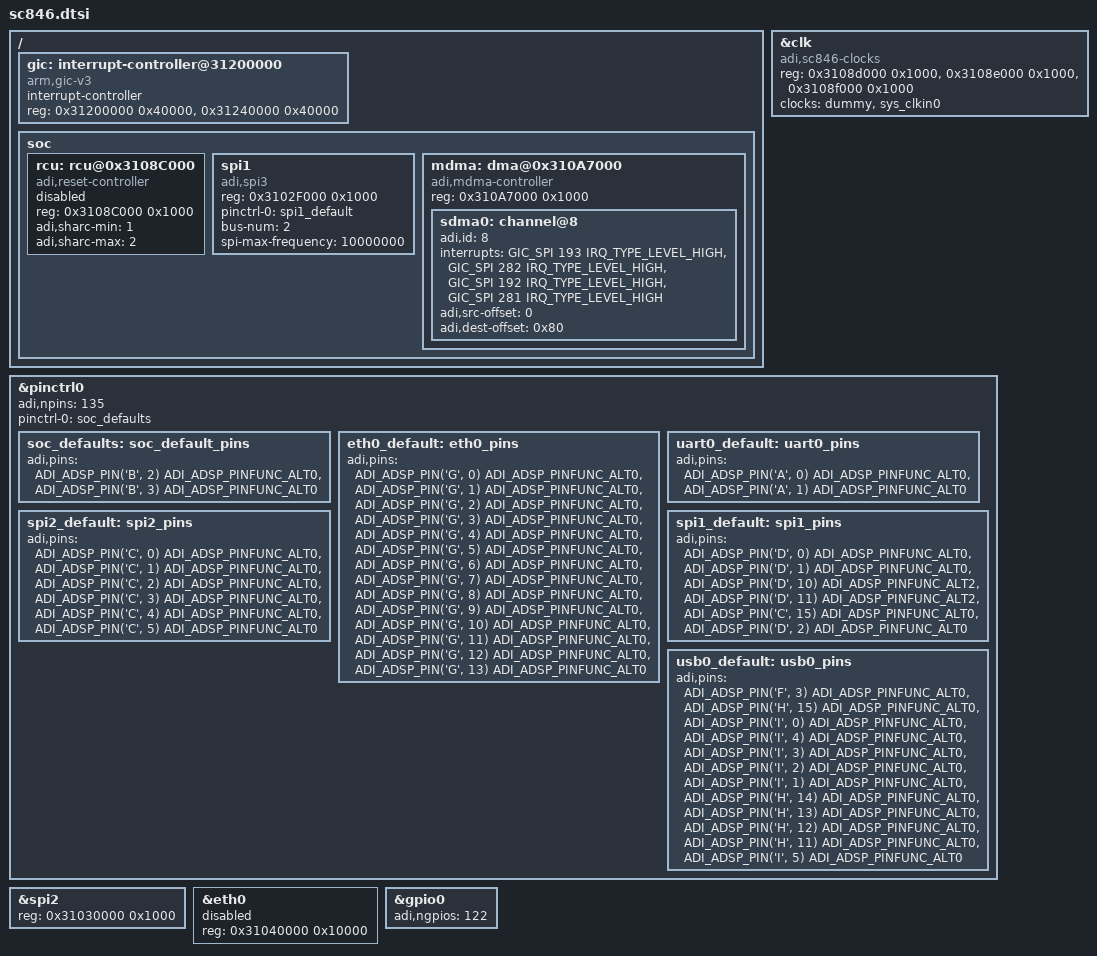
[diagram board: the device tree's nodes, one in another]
// SPDX-License-Identifier: GPL-2.0-or-later
/*
 * (C) Copyright 2026 - Analog Devices, Inc.
 */

#include "sc5xx.dtsi"

/ {
	gic: interrupt-controller@31200000 {
		compatible = "arm,gic-v3";
		#interrupt-cells = <3>;
		interrupt-controller;
		reg = <0x31200000 0x40000>,
		      <0x31240000 0x40000>;
	};

	soc {
		rcu: rcu@0x3108C000 {
			compatible = "adi,reset-controller";
			reg = <0x3108C000 0x1000>;
			adi,sharc-min = <1>;
			adi,sharc-max = <2>;
			status = "disabled";
		};

		spi1: spi1 {
			reg = <0x3102F000 0x1000>;
			compatible = "adi,spi3";
			#address-cells = <1>;
			#size-cells = <0>;
			pinctrl-names = "default";
			pinctrl-0 = <&spi1_default>;
			bus-num = <2>;
			spi-max-frequency = <10000000>;
			clock-names = "spi";
			status = "okay";
			bootph-pre-ram;
		};

		mdma: dma@0x310A7000 {
			compatible = "adi,mdma-controller";
			reg = <0x310A7000 0x1000>;
			status = "okay";
			#dma-cells = <1>;

			sdma0: channel@8 {
				adi,id = <8>;
				interrupts = <GIC_SPI 193 IRQ_TYPE_LEVEL_HIGH>,
					<GIC_SPI 282 IRQ_TYPE_LEVEL_HIGH>,
					<GIC_SPI 192 IRQ_TYPE_LEVEL_HIGH>,
					<GIC_SPI 281 IRQ_TYPE_LEVEL_HIGH>;
				interrupt-names = "complete", "error", "complete2", "error2";
				adi,src-offset = <0>;
				adi,dest-offset = <0x80>;
			};
		};
	};
};

&clk {
	reg = <0x3108d000 0x1000>,
		<0x3108e000 0x1000>,
		<0x3108f000 0x1000>;
	reg-names = "cgu0", "cgu1", "cdu";
	#clock-cells = <1>;
	clocks = <&dummy>, <&sys_clkin0>;
	clock-names = "dummy", "sys_clkin0";
	status = "okay";
	bootph-pre-ram;
};

&pinctrl0 {
	adi,npins = <135>;

	pinctrl-names = "default";

	pinctrl-0 = <&soc_defaults>;

	soc_defaults: soc_default_pins {
		bootph-pre-ram;
		adi,pins =  <ADI_ADSP_PIN('B', 2) ADI_ADSP_PINFUNC_ALT0>,
				<ADI_ADSP_PIN('B', 3) ADI_ADSP_PINFUNC_ALT0>;
	};

	eth0_default: eth0_pins {
		adi,pins = <ADI_ADSP_PIN('G', 0) ADI_ADSP_PINFUNC_ALT0>, /* management channel clock */
					<ADI_ADSP_PIN('G', 1) ADI_ADSP_PINFUNC_ALT0>,	/* management channel serial data */
					<ADI_ADSP_PIN('G', 2) ADI_ADSP_PINFUNC_ALT0>,	/* Recv Data */
					<ADI_ADSP_PIN('G', 3) ADI_ADSP_PINFUNC_ALT0>,	/* Recv Data */
					<ADI_ADSP_PIN('G', 4) ADI_ADSP_PINFUNC_ALT0>,	/* RXCLK(GigE)/Refclk(10/100) */
					<ADI_ADSP_PIN('G', 5) ADI_ADSP_PINFUNC_ALT0>,	/* RX control signal */
					<ADI_ADSP_PIN('G', 6) ADI_ADSP_PINFUNC_ALT0>,	/* Transmit Data */
					<ADI_ADSP_PIN('G', 7) ADI_ADSP_PINFUNC_ALT0>,	/* Transmit Data */
					<ADI_ADSP_PIN('G', 8) ADI_ADSP_PINFUNC_ALT0>,	/* Recv Data */
					<ADI_ADSP_PIN('G', 9) ADI_ADSP_PINFUNC_ALT0>,	/* Recv Data */
					<ADI_ADSP_PIN('G', 10) ADI_ADSP_PINFUNC_ALT0>,	/* TX control signal */
					<ADI_ADSP_PIN('G', 11) ADI_ADSP_PINFUNC_ALT0>,	/* Reference Clock */
					<ADI_ADSP_PIN('G', 12) ADI_ADSP_PINFUNC_ALT0>,	/* Transmit Data */
					<ADI_ADSP_PIN('G', 13) ADI_ADSP_PINFUNC_ALT0>;	/* Transmit Data */
	};

	uart0_default: uart0_pins {
		bootph-pre-ram;
		adi,pins = <ADI_ADSP_PIN('A', 0) ADI_ADSP_PINFUNC_ALT0>,		/* Tx */
					<ADI_ADSP_PIN('A', 1) ADI_ADSP_PINFUNC_ALT0>;	/* Rx */
	};

	spi1_default: spi1_pins {
		bootph-pre-ram;
		adi,pins = <ADI_ADSP_PIN('D', 0) ADI_ADSP_PINFUNC_ALT0>,			/* MISO */
					<ADI_ADSP_PIN('D', 1) ADI_ADSP_PINFUNC_ALT0>,		/* MOSI */
					<ADI_ADSP_PIN('D', 10) ADI_ADSP_PINFUNC_ALT2>,		/* Data 2 */
					<ADI_ADSP_PIN('D', 11) ADI_ADSP_PINFUNC_ALT2>,		/* Data 3 */
					<ADI_ADSP_PIN('C', 15) ADI_ADSP_PINFUNC_ALT0>,		/* SCLK */
					<ADI_ADSP_PIN('D', 2) ADI_ADSP_PINFUNC_ALT0>;		/* Sub(Slave) Select */
	};

	spi2_default: spi2_pins {
		bootph-pre-ram;
		adi,pins = <ADI_ADSP_PIN('C', 0) ADI_ADSP_PINFUNC_ALT0>,			/* MISO */
					<ADI_ADSP_PIN('C', 1) ADI_ADSP_PINFUNC_ALT0>,		/* MOSI */
					<ADI_ADSP_PIN('C', 2) ADI_ADSP_PINFUNC_ALT0>,		/* Data 2 */
					<ADI_ADSP_PIN('C', 3) ADI_ADSP_PINFUNC_ALT0>,		/* Data 3 */
					<ADI_ADSP_PIN('C', 4) ADI_ADSP_PINFUNC_ALT0>,		/* SCLK */
					<ADI_ADSP_PIN('C', 5) ADI_ADSP_PINFUNC_ALT0>;		/* Sub(Slave) Select */
	};

	usb0_default: usb0_pins {
		adi,pins = <ADI_ADSP_PIN('F', 3) ADI_ADSP_PINFUNC_ALT0>,			/* ULPI Stop Output Control */
					<ADI_ADSP_PIN('H', 15) ADI_ADSP_PINFUNC_ALT0>,		/* ULPI Next Data Control */
					<ADI_ADSP_PIN('I', 0) ADI_ADSP_PINFUNC_ALT0>,		/* ULPI Data Bus Control */
					<ADI_ADSP_PIN('I', 4) ADI_ADSP_PINFUNC_ALT0>,		/* ULPI Data 0 */
					<ADI_ADSP_PIN('I', 3) ADI_ADSP_PINFUNC_ALT0>,		/* ULPI Data 1 */
					<ADI_ADSP_PIN('I', 2) ADI_ADSP_PINFUNC_ALT0>,		/* ULPI Data 2 */
					<ADI_ADSP_PIN('I', 1) ADI_ADSP_PINFUNC_ALT0>,		/* ULPI Data 3 */
					<ADI_ADSP_PIN('H', 14) ADI_ADSP_PINFUNC_ALT0>,		/* ULPI Data 4 */
					<ADI_ADSP_PIN('H', 13) ADI_ADSP_PINFUNC_ALT0>,		/* ULPI Data 5 */
					<ADI_ADSP_PIN('H', 12) ADI_ADSP_PINFUNC_ALT0>,		/* ULPI Data 6 */
					<ADI_ADSP_PIN('H', 11) ADI_ADSP_PINFUNC_ALT0>,		/* ULPI Data 7 */
					<ADI_ADSP_PIN('I', 5) ADI_ADSP_PINFUNC_ALT0>;		/* ULPI Clock */
	};
};

&spi2 {
	reg = <0x31030000 0x1000>;
};

&eth0 {
	reg = <0x31040000 0x10000>;
	status = "disabled";
};

&clk {
	compatible = "adi,sc846-clocks";
};

&gpio0 {
	adi,ngpios = <122>;
};
